# nrf54l15_enga_flpr register map
Vendor: Nordic Semiconductor; Series: nrf54l; File version: 1
Registers are 32-bit, read-write, reset 0x0 unless marked. A register's access mark holds for its fields unless they carry their own. Offsets are from the block's base; [hi:lo] are bit positions; lines under a group give offsets from that group; {n}, {i} and the like mark numbered series.

## GLOBAL_GLITCHDET_S — Voltage glitch detectors
Base 0x5004B000
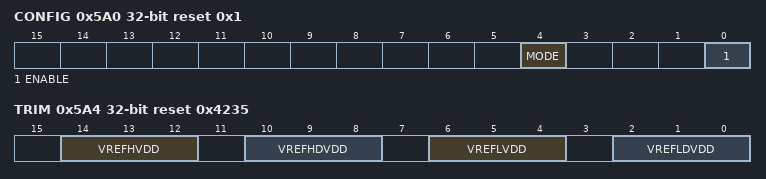
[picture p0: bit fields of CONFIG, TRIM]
0x5A0 CONFIG reset 0x1 — Configuration for glitch detector
  [4] MODE — Glitch detector mode
    0=High pass filter mode; 1=Cap divider mode
  [0] ENABLE — Enable glitch detector
    0=Disable glitch detector; 1=Enable glitch detector
0x5A4 TRIM reset 0x4235 — Trim configuration for glitch detector
  [14:12] VREFHVDD — Voltage trimming value for VREFH_VDD
    0=1V150 (0.150 V); 1=1V175 (0.175 V); 2=1V200 (1.200 V); 3=1V225 (1.225 V); 4=1V250 (1.250 V); 5=1V275 (1.275 V); 6=1V300 (1.300 V); 7=1V325 (1.325 V)
  [10:8] VREFHDVDD — Voltage trimming value for VREFH_DVDD
    0=0V950 (0.950 V); 1=0V975 (0.975 V); 2=1V000 (1.000 V); 3=1V025 (1.025 V); 4=1V050 (1.050 V); 5=1V075 (1.075 V); 6=1V100 (1.100 V); 7=1V125 (1.125 V)
  [6:4] VREFLVDD — Voltage trimming value for VREFL_VDD
    0=0V425 (0.425 V); 1=0V450 (0.450 V); 2=0V475 (0.475 V); 3=0V500 (0.500 V); 4=0V525 (0.525 V); 5=0V550 (0.550 V); 6=0V575 (0.575 V); 7=0V600 (0.600 V)
  [2:0] VREFLDVDD — Voltage trimming value for VREFL_DVDD
    0=0V675 (0.675 V); 1=0V700 (0.700 V); 2=0V725 (0.725 V); 3=0V750 (0.750 V); 4=0V775 (0.775 V); 5=0V800 (0.800 V); 6=0V825 (0.825 V); 7=0V850 (0.850 V)
0x5B0 DFT group — Unspecified
  0x00 ATB0CONFIG — Analog Test Bus 0 (ATB0) configuration
    [2:0] SELMUX — Select multiplexer for ATB0
      0=HiZ (High impedance); 1=VDDDIV (Measure/Force VDD_DIV voltage from external); 2=VDDDIG0V9 (Measure/Force VDD_DIG_0V9 voltage from external); 3=VSS; 4=GLITCHSRVDD3V0 (Internal signal - GLITCH_SR_VDD_3V0)
  0x04 ATB1CONFIG — Analog Test Bus 1 (ATB1) configuration
    [2:0] SELMUX — Select multiplexer for ATB1
      0=HiZ (High impedance); 1=VREFHVDD (Measure VREFH_VDD voltage); 2=VREFLVDD (Measure VREFL_VDD voltage); 3=VREFHDAVDD (Measure VREFH_DVDD voltage); 4=VREFLDVDD (Measure VREFL_DVDD voltage); 5=GLITCHSRDVDD3V0 (Internal signal - GLITCH_SR_DVDD_3V0)
  0x08 ATB2CONFIG — Analog Test Bus 2 (ATB2) configuration
    [1:0] SELMUX — Select multiplexer for ATB2
      0=HiZ (High impedance); 1=VTAMPORDVDD3V0 (Internal signal - VTAMP_OR_DVDD_3V0); 2=VTAMPORVDD3V0 (Internal signal - VTAMP_OR_VDD_3V0); 3=GLITCHNINT3V0 (Internal signal - GLITCH_N_INT_3V0)

## GLOBAL_GPIOHSPADCTRL_NS — GPIO high-speed pad control 0
Base 0x40050400
Same registers: GLOBAL_GPIOHSPADCTRL_S 0x50050400
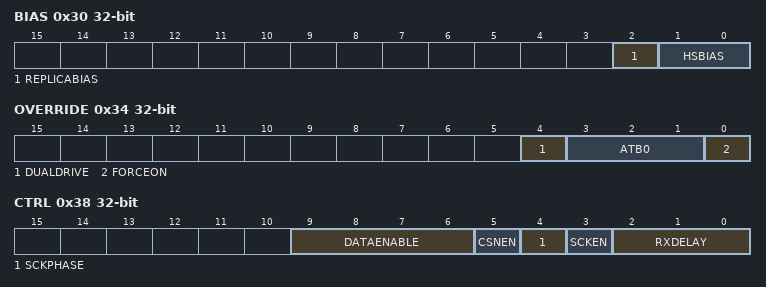
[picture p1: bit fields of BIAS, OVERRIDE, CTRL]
0x30 BIAS — Bias control
  [2] REPLICABIAS — Bias setting for replica pad
  [1:0] HSBIAS — Bias setting for high-speed pad
0x34 OVERRIDE — Override control
  [4] DUALDRIVE — Drive pad from both high-speed pad and regular pad (when highspeed is enabled)
  [3:1] ATB0 — ATB0 settings
    7=BiasTrim (Unspecified); 6=BiasSupply (Unspecified); 5=BiasPTAT (Unspecified)
  [0] FORCEON
0x38 CTRL — HS pad control register
  [9:6] DATAENABLE — Enable re-clocking for data bit 0-3 through pad-sync module
  [5] CSNEN — CSN enable
  [4] SCKPHASE
  [3] SCKEN — Enable SCK
  [2:0] RXDELAY — RXDELAY setting

## GLOBAL_P2_NS — GPIO Port 0
Base 0x40050400; alternate view of GLOBAL_GPIOHSPADCTRL_NS
Same registers: GLOBAL_P1_NS 0x400D8200, GLOBAL_P0_NS 0x4010A000, GLOBAL_P2_S 0x50050400 (alternate view of GLOBAL_GPIOHSPADCTRL_S), GLOBAL_P1_S 0x500D8200, GLOBAL_P0_S 0x5010A000
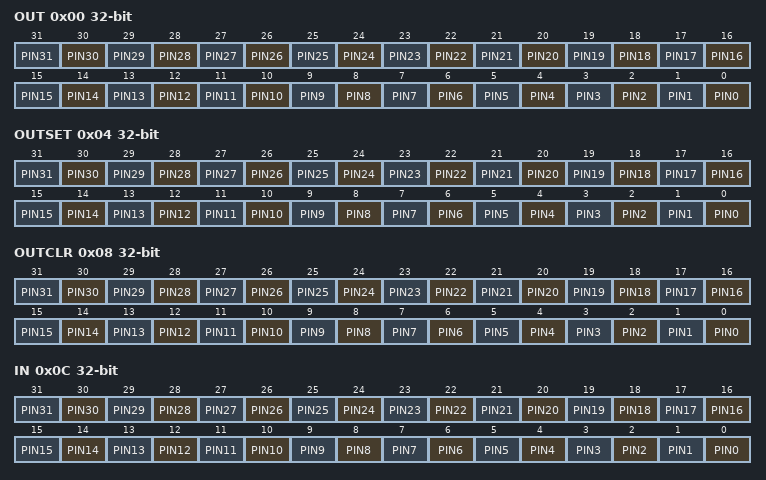
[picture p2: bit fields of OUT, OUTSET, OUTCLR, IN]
0x00 OUT — Write GPIO port
  [all] fields
    0=Low (Pin driver is low); 1=High (Pin driver is high)
  [n] PIN{n} (n=0..31)
0x04 OUTSET write-1-sets — Set individual bits in GPIO port
  [all] fields
    on read: 0=Low (Read: pin driver is low); 1=High (Read: pin driver is high) | on write: 1=Set (Write: writing a '1' sets the pin high; writing a '0' has no effect)
  [n] PIN{n} (n=0..31)
0x08 OUTCLR write-1-clears — Clear individual bits in GPIO port
  [all] fields
    on read: 0=Low (Read: pin driver is low); 1=High (Read: pin driver is high) | on write: 1=Clear (Write: writing a '1' sets the pin low; writing a '0' has no effect)
  [n] PIN{n} (n=0..31)
0x0C IN ro — Read GPIO port
  [all] fields
    0=Low (Pin input is low); 1=High (Pin input is high)
  [n] PIN{n} (n=0..31)
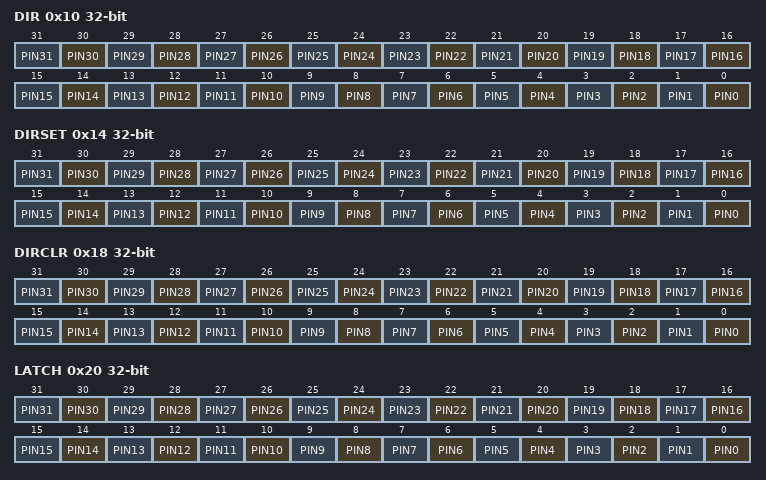
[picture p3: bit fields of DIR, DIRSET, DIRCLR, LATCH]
0x10 DIR — Direction of GPIO pins
  [all] fields
    0=Input (Pin set as input); 1=Output (Pin set as output)
  [n] PIN{n} (n=0..31)
0x14 DIRSET write-1-sets
  [all] fields
    on read: 0=Input (Read: pin set as input); 1=Output (Read: pin set as output) | on write: 1=Set (Write: writing a '1' sets pin to output; writing a '0' has no effect)
  [n] PIN{n} (n=0..31) — Set as output pin {n}
0x18 DIRCLR write-1-clears — DIR clear register
  [all] fields
    on read: 0=Input (Read: pin set as input); 1=Output (Read: pin set as output) | on write: 1=Clear (Write: writing a '1' sets pin to input; writing a '0' has no effect)
  [n] PIN{n} (n=0..31) — Set as input pin {n}
0x20 LATCH — Latch register indicating what GPIO pins that have met the criteria set in the PIN_CNF[n].SENSE registers
  [all] fields
    0=NotLatched (Criteria has not been met); 1=Latched (Criteria has been met)
  [n] PIN{n} (n=0..31) — Status on whether PIN{n} has met criteria set in PIN_CNF[{n}].SENSE register. Write '1' to clear.
0x24 DETECTMODE — Select between default DETECT signal behavior and LDETECT mode
  [0] DETECTMODE
    0=Default (DETECT directly connected to PIN DETECT signals); 1=LDETECT (Use the latched LDETECT behavior)
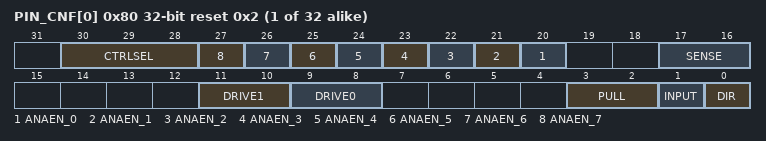
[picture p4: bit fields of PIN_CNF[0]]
{0x80+4i} PIN_CNF[{i}] (i=0..31) reset 0x2 — Description collection: Pin n configuration of GPIO pin
  [30:28] CTRLSEL — Select which module has direct control over this pin
    0=GPIO (GPIO or peripherals with PSEL registers); 1=VPR (VPR processor); 4=GRTC (GRTC peripheral)
  [n+20] ANAEN_{n} (n=0..7) — Control of analog slices for pads with ATB functionality. LSB in ANAEN control slice 0, and so on.
    0=Disabled (Slice disabled); 1=Enabled (Slice enabled)
  [17:16] SENSE — Pin sensing mechanism
    0=Disabled; 2=High (Sense for high level); 3=Low (Sense for low level)
  [11:10] DRIVE1 — Drive configuration for '1'
    0=S1 (Standard '1'); 1=H1 (High drive '1'); 2=D1 (Disconnect '1'(normally used for wired-or connections)); 3=E1 (Extra high drive '1')
  [9:8] DRIVE0 — Drive configuration for '0'
    0=S0 (Standard '0'); 1=H0 (High drive '0'); 2=D0 (Disconnect '0'(normally used for wired-or connections)); 3=E0 (Extra high drive '0')
  [3:2] PULL — Pull configuration
    0=Disabled (No pull); 1=Pull down on pin; 3=Pull up on pin
  [1] INPUT — Connect or disconnect input buffer
    0=Connect input buffer; 1=Disconnect input buffer
  [0] DIR — Pin direction. Same physical register as DIR register
    0=Input (Configure pin as an input pin); 1=Output (Configure pin as an output pin)

## Notices in the file
Copyright (c) 2010 - 2024, Nordic Semiconductor ASA
All rights reserved.
Redistribution and use in source and binary forms, with or without modification,
are permitted provided that the following conditions are met:
1. Redistributions of source code must retain the above copyright notice, this
list of conditions and the following disclaimer.
2. Redistributions in binary form, except as embedded into a Nordic
Semiconductor ASA integrated circuit in a product or a software update for
such product, must reproduce the above copyright notice, this list of
conditions and the following disclaimer in the documentation and/or other
materials provided with the distribution.
3. Neither the name of Nordic Semiconductor ASA nor the names of its
contributors may be used to endorse or promote products derived from this
software without specific prior written permission.
4. This software, with or without modification, must only be used with a
Nordic Semiconductor ASA integrated circuit.
5. Any software provided in binary form under this license must not be reverse
engineered, decompiled, modified and/or disassembled.
THIS SOFTWARE IS PROVIDED BY NORDIC SEMICONDUCTOR ASA "AS IS" AND ANY EXPRESS
OR IMPLIED WARRANTIES, INCLUDING, BUT NOT LIMITED TO, THE IMPLIED WARRANTIES
OF MERCHANTABILITY, NONINFRINGEMENT, AND FITNESS FOR A PARTICULAR PURPOSE ARE
DISCLAIMED. IN NO EVENT SHALL NORDIC SEMICONDUCTOR ASA OR CONTRIBUTORS BE
LIABLE FOR ANY DIRECT, INDIRECT, INCIDENTAL, SPECIAL, EXEMPLARY, OR
CONSEQUENTIAL DAMAGES (INCLUDING, BUT NOT LIMITED TO, PROCUREMENT OF SUBSTITUTE
GOODS OR SERVICES; LOSS OF USE, DATA, OR PROFITS; OR BUSINESS INTERRUPTION)
HOWEVER CAUSED AND ON ANY THEORY OF LIABILITY, WHETHER IN CONTRACT, STRICT
LIABILITY, OR TORT (INCLUDING NEGLIGENCE OR OTHERWISE) ARISING IN ANY WAY OUT
OF THE USE OF THIS SOFTWARE, EVEN IF ADVISED OF THE POSSIBILITY OF SUCH DAMAGE.
